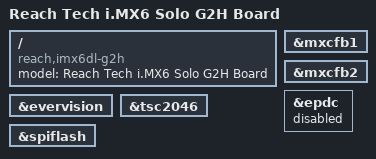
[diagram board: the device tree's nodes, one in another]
/*
 * Copyright 2013 Freescale Semiconductor, Inc.
 *
 * Author: Fabio Estevam <fabio.estevam@freescale.com>
 *
 * This program is free software; you can redistribute it and/or modify
 * it under the terms of the GNU General Public License version 2 as
 * published by the Free Software Foundation.
 *
 */
/dts-v1/;

#include <dt-bindings/interrupt-controller/irq.h>
#include "imx6dl.dtsi"
#include "imx6qdl-g2h.dtsi"

/ {
	model = "Reach Tech i.MX6 Solo G2H Board";
	compatible = "reach,imx6dl-g2h", "fsl,imx6dl";
};

&mxcfb1 {
	status = "okay";
};

&mxcfb2 {
	status = "okay";
};

&epdc {
	status = "disabled";
};

&evervision {
	status = "okay";
};

&tsc2046 {
	status = "okay";
};

&spiflash {
	status = "okay";
};
